# CM41x_M0 register map
Vendor: Analog Devices; Series: CM41x_M0; File version: 1p0
CPU: CM0 r0p0, little endian, MPU, FPU, 4 interrupt priority bits
Registers are 32-bit, read-write, reset 0x0 unless marked. A register's access mark holds for its fields unless they carry their own. Offsets are from the block's base; [hi:lo] are bit positions; {n}, {i} and the like mark numbered series; 'fields as' and 'values as' point back to an identical list.

## PWM0 — Pulse-Width Modulator
Base 0x40028000
Same registers: PWM1 0x40029000, PWM2 0x4002A000
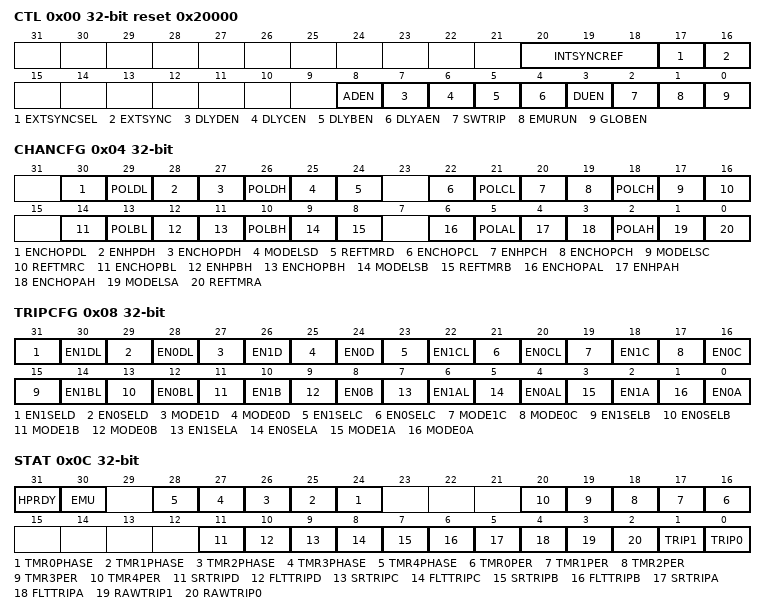
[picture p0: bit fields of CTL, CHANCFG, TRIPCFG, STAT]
0x00 CTL reset 0x20000 — Control Register
  [20:18] INTSYNCREF — Timer reference for Internal Sync
    {v}=INTSYNC_{v} (PWMTMR{v} provides sync reference) (v=0..4)
  [17] EXTSYNCSEL — External Sync Select
    0=EXTSYNC_ASYNC (Asynchronous External Sync); 1=EXTSYNC_SYNC (Synchronous External Sync)
  [16] EXTSYNC — External Sync
    0=INTSYNC (Internal sync used); 1=EXTSYNC (External sync used)
  [8] ADEN — Asymmetric Dead-time Enable
  [7] DLYDEN — Enable Delay Counter for Channel D
    0=DLYD_DIS (Disable); 1=DLYD_EN (Enable)
  [6] DLYCEN — Enable Delay Counter for Channel C
    0=DLYC_DIS (Disable); 1=DLYC_EN (Enable)
  [5] DLYBEN — Enable Delay Counter for Channel B
    0=DLYB_DIS (Disable); 1=DLYB_EN (Enable)
  [4] DLYAEN — Enable Delay Counter for Channel A
    0=DLYA_DIS (Disable); 1=DLYA_EN (Enable)
  [3] DUEN — Double Update Mode Enable
  [2] SWTRIP — Software Trip
  [1] EMURUN — Output Behavior During Emulation Mode
    0=EMURUN_DIS (Disable Outputs); 1=EMURUN_EN (Enable Outputs)
  [0] GLOBEN — Module Enable
    0=PWM_DIS (Disable); 1=PWM_EN (Enable)
0x04 CHANCFG — Channel Configuration Register
  [30] ENCHOPDL — Channel D Gate Chopping Enable Low Side
    0=CHOPDL_DIS (Disable Chopping Channel D Low Side); 1=CHOPDL_EN (Enable Chopping Channel D Low Side)
  [29] POLDL — Channel D low side Polarity
    0=DL_ACTLO (Active Low); 1=DL_ACTHI (Active High)
  [28] ENHPDH — Channel D heightened-precision enable for high side Output
    0=HPDH_DIS (Disable HP Output Channel D High); 1=HPDH_EN (Enable HP Output Channel D High)
  [27] ENCHOPDH — Channel D Gate Chopping Enable High Side
    0=CHOPDH_DIS (Disable Chopping Channel D High Side); 1=CHOPDH_EN (Enable Chopping Channel D High Side)
  [26] POLDH — Channel D High side Polarity
    0=DH_ACTLO (Active Low); 1=DH_ACTHI (Active High)
  [25] MODELSD — Channel D Mode of low Side Output
    0=LOD_INVHI (Invert of high output); 1=LOD_IND (Independent control)
  [24] REFTMRD — Channel D Timer Reference
    0=PWMTMR0 is Channel D reference; 1=PWMTMR4 is Channel D reference
  [22] ENCHOPCL — Channel C Gate Chopping Enable Low Side
    0=CHOPCL_DIS (Disable Chopping Channel C Low Side); 1=CHOPCL_EN (Enable Chopping Channel C Low Side)
  [21] POLCL — Channel C low side Polarity
    0=CL_ACTLO (Active Low); 1=CL_ACTHI (Active High)
  [20] ENHPCH — Channel C heightened-precision enable for high side Output
    0=HPCH_DIS (Disable HP Output Channel C High); 1=HPCH_EN (Enable HP Output Channel C High)
  [19] ENCHOPCH — Channel C Gate Chopping Enable High Side
    0=CHOPCH_DIS (Disable Chopping Channel C High Side); 1=CHOPCH_EN (Enable Chopping Channel C High Side)
  [18] POLCH — Channel C High side Polarity
    0=CH_ACTLO (Active Low); 1=CH_ACTHI (Active High)
  [17] MODELSC — Channel C Mode of low Side Output
    0=LOC_INVHI (Invert of high output); 1=LOC_IND (Independent control)
  [16] REFTMRC — Channel C Timer Reference
    0=PWMTMR0 is Channel C reference; 1=PWMTMR3 is Channel C reference
  [14] ENCHOPBL — Channel B Gate Chopping Enable Low Side
    0=CHOPBL_DIS (Disable Chopping Channel B Low Side); 1=CHOPBL_EN (Enable Chopping Channel B Low Side)
  [13] POLBL — Channel B low side Polarity
    0=BL_ACTLO (Active Low); 1=BL_ACTHI (Active High)
  [12] ENHPBH — Channel B heightened-precision enable for high side Output
    0=HPBH_DIS (Disable HP Output Channel B High); 1=HPBH_EN (Enable HP Output Channel B High)
  [11] ENCHOPBH — Channel B Gate Chopping Enable High Side
    0=CHOPBH_DIS (Disable Chopping Channel B High Side); 1=CHOPBH_EN (Enable Chopping Channel B High Side)
  [10] POLBH — Channel B High side Polarity
    0=BH_ACTLO (Active Low); 1=BH_ACTHI (Active High)
  [9] MODELSB — Channel B Mode of low Side Output
    0=LOB_INV (Invert of high output); 1=LOB_IND (Independent control)
  [8] REFTMRB — Channel B Timer Reference
    0=PWMTMR0 is Channel B reference; 1=PWMTMR2 is Channel B reference
  [6] ENCHOPAL — Channel A Gate Chopping Enable Low Side
    0=CHOPAL_DIS (Disable Chopping Channel A Low Side); 1=CHOPAL_EN (Enable Chopping Channel A Low Side)
  [5] POLAL — Channel A low side Polarity
    0=AL_ACTLO (Active Low); 1=AL_ACTHI (Active High)
  [4] ENHPAH — Channel A heightened-precision enable for high side Output
    0=HPAH_DIS (Disable HP Output Channel A High); 1=HPAH_EN (Enable HP Output Channel A High)
  [3] ENCHOPAH — Channel A Gate Chopping Enable High Side
    0=CHOPAH_DIS (Disable Chopping Channel A High Side); 1=CHOPAH_EN (Enable Chopping Channel A High Side)
  [2] POLAH — Channel A High side Polarity
    0=AH_ACTLO (Active Low); 1=AH_ACTHI (Active High)
  [1] MODELSA — Channel A Mode of low Side Output
    0=LOA_INVHI (Invert of high output); 1=LOA_IND (Independent control)
  [0] REFTMRA — Channel A Timer Reference
    0=PWMTMR0 is Channel A reference; 1=PWMTMR1 is Channel A reference
0x08 TRIPCFG — Trip Configuration Register
  [31] EN1SELD — TRIP1 Enable Select for Channel D Low Side
    0=TRIP1SEL_EN0D (Select EN0D for Channel D Low Side Trip1 Enable); 1=TRIP1SEL_EN0DL (Select EN0DL for Channel D Low Side Trip1 Enable)
  [30] EN1DL — Enable TRIP1 for Channel D Low Side
    0=TRIP1DL_DIS (Disable Trip1 for Channel D Low Side); 1=TRIP1DL_EN (Enable Trip1 for Channel D Low Side)
  [29] EN0SELD — TRIP0 Enable Select for Channel D Low Side
    0=TRIP0SEL_EN0D (Select EN0D for Channel D Low Side Trip0 Enable); 1=TRIP0SEL_EN0DL (Select EN0DL for Channel D Low Side Trip0 Enable)
  [28] EN0DL — Enable TRIP0 for Channel D Low Side
    0=TRIP0DL_DIS (Disable Trip0 for Channel D Low Side); 1=TRIP0DL_EN (Enable Trip0 for Channel D Low Side)
  [27] MODE1D — Mode of TRIP1 for Channel D
    0=TRIP1D_FLT (Fault Trip on TRIP1 Input); 1=TRIP1D_RSTRT (Self Restart on TRIP1 Input)
  [26] EN1D — Enable TRIP1 for Channel D
    0=TRIP1D_DIS (Disable TRIP1 for Channel D); 1=TRIP1D_EN (Enable TRIP1 for Channel D)
  [25] MODE0D — Mode of TRIP0 for Channel D
    0=TRIP0D_FLT (Fault Trip on TRIP0 Input); 1=TRIP0D_RSTRT (Self Restart on TRIP0 Input)
  [24] EN0D — Enable TRIP0 for Channel D
    0=TRIP0D_DIS (Disable TRIP0 for Channel D); 1=TRIP0D_EN (Enable TRIP0 for Channel D)
  [23] EN1SELC — TRIP1 Enable Select for Channel C Low Side
    0=TRIP1SEL_EN0C (Select EN0C for Channel C Low Side Trip1 Enable); 1=TRIP1SEL_EN0CL (Select EN0CL for Channel C Low Side Trip1 Enable)
  [22] EN1CL — Enable TRIP1 for Channel C Low Side
    0=TRIP1CL_DIS (Disable Trip1 for Channel C Low Side); 1=TRIP1CL_EN (Enable Trip1 for Channel C Low Side)
  [21] EN0SELC — TRIP0 Enable Select for Channel C Low Side
    0=TRIP0SEL_EN0C (Select EN0C for Channel C Low Side Trip0 Enable); 1=TRIP0SEL_EN0CL (Select EN0CL for Channel C Low Side Trip0 Enable)
  [20] EN0CL — Enable TRIP0 for Channel C Low Side
    0=TRIP0CL_DIS (Disable Trip0 for Channel C Low Side); 1=TRIP0CL_EN (Enable Trip0 for Channel C Low Side)
  [19] MODE1C — Mode of TRIP1 for Channel C
    0=TRIP1C_FLT (Fault Trip on TRIP1 Input); 1=TRIP1C_RSTRT (Self Restart on TRIP1 Input)
  [18] EN1C — Enable TRIP1 as a trip source for Channel C
    0=TRIP1C_DIS (Disable TRIP1 for Channel C); 1=TRIP1C_EN (Enable TRIP1 for Channel C)
  [17] MODE0C — Mode of TRIP0 for Channel C
    0=TRIP0C_FLT (Fault Trip on TRIP0 Input); 1=TRIP0C_RSTRT (Self Restart on TRIP0 Input)
  [16] EN0C — Enable TRIP0 for Channel C
    0=TRIP0C_DIS (Disable TRIP0 for Channel C); 1=TRIP0C_EN (Enable TRIP0 for Channel C)
  [15] EN1SELB — TRIP1 Enable Select for Channel B Low Side
    0=TRIP1SEL_EN0B (Select EN0B for Channel B Low Side Trip1 Enable); 1=TRIP1SEL_EN0BL (Select EN0BL for Channel B Low Side Trip1 Enable)
  [14] EN1BL — Enable TRIP1 as a trip source for Channel B Low Side
    0=TRIP1BL_DIS (Disable Trip1 for Channel B Low Side); 1=TRIP1BL_EN (Enable Trip1 for Channel B Low Side)
  [13] EN0SELB — TRIP0 Enable Select for Channel B Low Side
    0=TRIP0SEL_EN0B (Select EN0B for Channel B Low Side Trip0 Enable); 1=TRIP0SEL_EN0BL (Select EN0BL for Channel B Low Side Trip0 Enable)
  [12] EN0BL — Enable TRIP0 for Channel B Low Side
    0=TRIP0BL_DIS (Disable Trip0 for Channel B Low Side); 1=TRIP0BL_EN (Enable Trip0 for Channel B Low Side)
  [11] MODE1B — Mode of TRIP1 for Channel B
    0=TRIP1B_FLT (Fault Trip on TRIP1 Input); 1=TRIP1B_RSTRT (Self Restart on TRIP1 Input)
  [10] EN1B — Enable TRIP1 for Channel B
    0=TRIP1B_DIS (Disable TRIP1 for Channel B); 1=TRIP1B_EN (Enable TRIP1 for Channel B)
  [9] MODE0B — Mode of TRIP0 for Channel B
    0=TRIP0B_FLT (Fault Trip on TRIP0 Input); 1=TRIP0B_RSTRT (Self Restart on TRIP0 Input)
  [8] EN0B — Enable TRIP0 as a trip source for Channel B
    0=TRIP0B_DIS (Disable TRIP0 for Channel B); 1=TRIP0B_EN (Enable TRIP0 for Channel B)
  [7] EN1SELA — TRIP1 Enable Select for Channel A Low Side
    0=TRIP1SEL_EN0A (Select EN0A for Channel A Low Side Trip1 Enable); 1=TRIP1SEL_EN0AL (Select EN0AL for Channel A Low Side Trip1 Enable)
  [6] EN1AL — Enable TRIP1 for Channel A Low Side
    0=TRIP1AL_DIS (Disable Trip1 for Channel A Low Side); 1=TRIP1AL_EN (Enable Trip1 for Channel A Low Side)
  [5] EN0SELA — TRIP0 Enable Select for Channel A Low Side
    0=TRIP0SEL_EN0A (Select EN0A for Channel A Low Side Trip0 Enable); 1=TRIP0SEL_EN0AL (Select EN0AL for Channel A Low Side Trip0 Enable)
  [4] EN0AL — Enable TRIP0 for Channel A Low Side
    0=TRIP0AL_DIS (Disable Trip0 for Channel A Low Side); 1=TRIP0AL_EN (Enable Trip0 for Channel A Low Side)
  [3] MODE1A — Mode of TRIP1 for Channel A
    0=TRIP1A_FLT (Fault Trip on TRIP1 Input); 1=TRIP1A_RSTRT (Self Restart on TRIP1 Input)
  [2] EN1A — Enable TRIP1 as a trip source for Channel A
    0=TRIP1A_DIS (Disable TRIP1 for Channel A); 1=TRIP1A_EN (Enable TRIP1 for Channel A)
  [1] MODE0A — Mode of TRIP0 for Channel A
    0=TRIP0A_FLT (Fault Trip on TRIP0 Input); 1=TRIP0A_RSTRT (Self Restart on TRIP0 Input)
  [0] EN0A — Enable TRIP0 as a trip source for Channel A
    0=TRIP0A_DIS (Disable TRIP0 for Channel A); 1=TRIP0A_EN (Enable TRIP0 for Channel A)
0x0C STAT — Status Register
  [31] HPRDY ro — Heightened-Precision Ready Status
    0=NOT_HPRDY (HPPWM Not Ready For Operation); 1=HPRDY (HPPWM Ready For Operation)
  [30] EMU range 0x00000000..0x00000001 — Emulator Status
  [n+24] TMR{n}PHASE (n=0..4) — PWMTMR{n} Phase Status
    0=TMR{n}PH1 (1st Half Phase); 1=TMR{n}PH2 (2nd Half Phase)
  [n+16] TMR{n}PER (n=0..4) — PWMTMR{n} Period Boundary Status
    0=NOT_PER{n} (PWMTMR{n} period boundary not reached); 1=PER{n} (PWMTMR{n} period boundary reached)
  [11] SRTRIPD ro — Self-Restart Trip Status for Channel D
    0=SRD_NOTRIP (Channel D Self-Restart Trip Status is "not tripped"); 1=SRD_TRIP (Channel D Self-Restart Trip Status is "tripped")
  [10] FLTTRIPD — Fault Trip Status for Channel D
    0=FLTD_NOTRIP (Channel D Fault Trip Status is "not tripped"); 1=FLTD_TRIP (Channel D Fault Trip Status is "tripped")
  [9] SRTRIPC ro — Self-Restart Trip Status for Channel C
    0=SRC_NOTRIP (Channel C Self-Restart Trip Status is "not tripped"); 1=SRC_TRIP (Channel C Self-Restart Trip Status is "tripped")
  [8] FLTTRIPC — Fault Trip Status for Channel C
    0=FLTC_NOTRIP (Channel C Fault Trip Status is "not tripped"); 1=FLTC_TRIP (Channel C Fault Trip Status is "tripped")
  [7] SRTRIPB ro — Self-Restart Trip Status for Channel B
    0=SRB_NOTRIP (Channel B Self-Restart Trip Status is "not tripped"); 1=SRB_TRIP (Channel B Self-Restart Trip Status is "tripped")
  [6] FLTTRIPB — Fault Trip Status for Channel B
    0=FLTB_NOTRIP (Channel B Fault Trip Status is "not tripped"); 1=FLTB_TRIP (Channel A Fault Trip Status is "tripped")
  [5] SRTRIPA ro — Self-Restart Trip Status for Channel A
    0=SRA_NOTRIP (Channel A Self-Restart Trip Status is "not tripped"); 1=SRA_TRIP (Channel A Self-Restart Trip Status is "tripped")
  [4] FLTTRIPA — Fault Trip Status for Channel A
    0=FLTA_NOTRIP (Channel A Fault Trip Status is "not tripped"); 1=FLTA_TRIP (Channel A Fault Trip Status is "tripped")
  [3] RAWTRIP1 ro — Raw Trip 1 Status
    0=TRIP1LVL_LO (TRIP1 Level is Low); 1=TRIP1LVL_HI (TRIP1 Level is High)
  [2] RAWTRIP0 ro — Raw Trip 0 Status
    0=TRIP0LVL_LO (TRIP0 Level is Low); 1=TRIP0LVL_HI (TRIP0 Level is High)
  [1] TRIP1 — Status bit set when TRIP1 is active low
    0=NO_TRIP1 (TRIP1 status is "not tripped"); 1=TRIP1 (TRIP1 status is "tripped" (active low))
  [0] TRIP0 — Status bit set when TRIP0 is active low
    0=NO_TRIP0 (TRIP0 status is "not tripped"); 1=TRIP0 (TRIP0 status is "tripped" (active low))
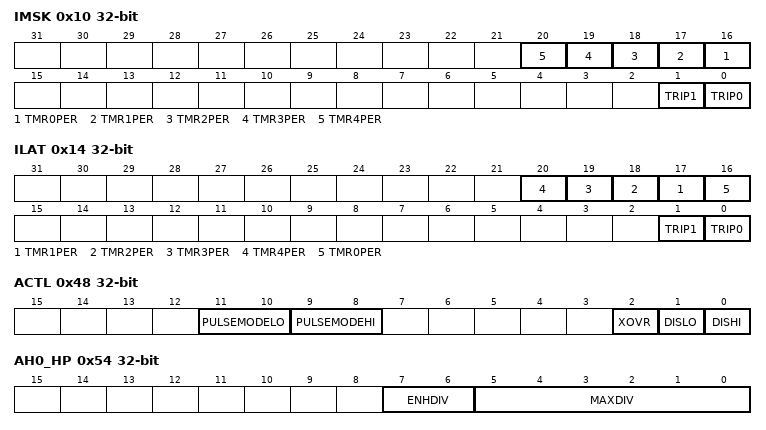
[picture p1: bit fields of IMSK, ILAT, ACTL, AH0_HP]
0x10 IMSK — Interrupt Mask Register
  [n+16] TMR{n}PER (n=0..4) — PWMTMR{n} Period Boundary Interrupt Enable
    0=PER{n}_MSK (Mask PWMTMR{n} Period Interrupt); 1=PER{n}_UMSK (Unmask PWMTMR{n} Period Interrupt)
  [1] TRIP1 — TRIP1 Interrupt Enable
    0=TRIP1_MSK (Mask TRIP1 Interrupt); 1=TRIP1_UMSK (Unmask TRIP1 Interrupt)
  [0] TRIP0 — TRIP0 Interrupt Enable
    0=TRIP0_MSK (Mask TRIP0 Interrupt); 1=TRIP0_UMSK (Unmask TRIP0 Interrupt)
0x14 ILAT — Interrupt Latch Register
  [n+16] TMR{n}PER (n=1..4) — PWMTMR{n} Period Latched Interrupt Status
    0=PER{n}_INTLO (No Interrupt Latched); 1=PER{n}_INTHI (Interrupt Latched)
  [16] TMR0PER — PWMTMR0 Period Boundary Interrupt Latched Status
    0=PER0_INTLO (No Interrupt Latched); 1=PER0_INTHI (Interrupt Latched)
  [1] TRIP1 — TRIP1 Interrupt Latched Status
    0=TRIP1_INTLO (No Interrupt Latched); 1=TRIP1_INTHI (Interrupt Latched)
  [0] TRIP0 — TRIP0 Interrupt Latched Status
    0=TRIP0_INTLO (No Interrupt Latched); 1=TRIP0_INTHI (Interrupt Latched)
0x18 CHOPCFG — Chop Configuration Register
  [7:0] VALUE range 0x00000000..0x000000FF — Gate Chopping Divisor
0x20 SYNC_WID reset 0x3FF — Sync Pulse Width Register
  [9:0] VALUE range 0x00000000..0x000003FF — Sync Pulse Width
{0x24+4i} TM{i} (i=0..4) — Timer {i} Period Register
  [15:0] VALUE range 0x00000000..0x0000FFFF — Timer PWMTMR{i} Period Value
0x38 DLYA — Channel A Delay Register
  [15:0] VALUE range 0x00000000..0x0000FFFF — Channel A Delay Value
0x3C DLYB — Channel B Delay Register
  [15:0] VALUE range 0x00000000..0x0000FFFF — Channel B Delay Value
0x40 DLYC — Channel C Delay Register
  [15:0] VALUE range 0x00000000..0x0000FFFF — Channel C Delay Value
0x44 DLYD — Channel D Delay Register
  [15:0] VALUE range 0x00000000..0x0000FFFF — Channel D Delay Value
0x48 ACTL — Channel A Control Register
  [11:10] PULSEMODELO — Low Side Output Pulse Position
    0=SYM_LO (Symmetrical); 1=ASYM_LO (Asymmetrical); 2=LEFT_LO (Left Half); 3=RIGHT_LO (Right Half)
  [9:8] PULSEMODEHI — High Side Output Pulse Position
    0=SYM_HI (Symmetrical); 1=ASYM_HI (Asymmetrical); 2=LEFT_HI (Left Half); 3=RIGHT_HI (Right Half)
  [2] XOVR — high-low Crossover Enable
    0=XOVR_DIS (Disable Crossover); 1=XOVR_EN (Enable Crossover)
  [1] DISLO — Channel Low Side Output Disable
    0=LO_DIS (Enable Low Side Output); 1=LO_EN (Disable Low Side Output)
  [0] DISHI — Channel High Side Output Disable
    0=HI_DIS (Enable High Side Output); 1=HI_EN (Disable High Side Output)
0x4C AH0 — Channel A-High Duty-0 Register
  [15:0] DUTY range 0x00000000..0x0000FFFF — Duty Cycle Asserted Count
0x50 AH1 — Channel A-High Duty-1 Register
  [15:0] DUTY range 0x00000000..0x0000FFFF — Duty Cycle De-Asserted Count
0x54 AH0_HP — Channel A-High Heightened-Precision Duty-0 Register
  [7:6] ENHDIV range 0x00000000..0x00000003 — Enhanced Precision Divider Bits
  [5:0] MAXDIV range 0x00000000..0x0000003F — Maximum Precision Supplementary Divider Bits
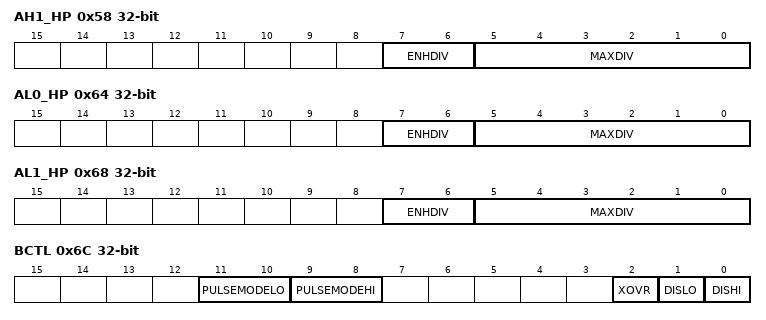
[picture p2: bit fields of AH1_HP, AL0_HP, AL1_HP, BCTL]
0x58 AH1_HP — Channel A-High Heightened-Precision Duty-1 Register
  fields as AH0_HP
0x5C AL0 — Channel A-Low Duty-0 Register
  [15:0] DUTY range 0x00000000..0x0000FFFF — Duty Cycle Asserted Count
0x60 AL1 — Channel A-Low Duty-1 Register
  fields as AH1
0x64 AL0_HP — Channel A-Low Heightened-Precision Duty-0 Register
  fields as AH0_HP
0x68 AL1_HP — Channel A-Low Heightened-Precision Duty-1 Register
  fields as AH0_HP
0x6C BCTL — Channel B Control Register
  [11:10] PULSEMODELO — Low Side Output Pulse Position
  [9:8] PULSEMODEHI — High Side Output Pulse Position
  [2] XOVR — high-low Crossover Enable
  [1] DISLO — Channel Low Side Output Disable
  [0] DISHI — Channel High Side Output Disable
0x70 BH0 — Channel B-High Duty-0 Register
  [15:0] DUTY range 0x00000000..0x0000FFFF — Duty Cycle Asserted Count
0x74 BH1 — Channel B-High Duty-1 Register
  fields as AH1
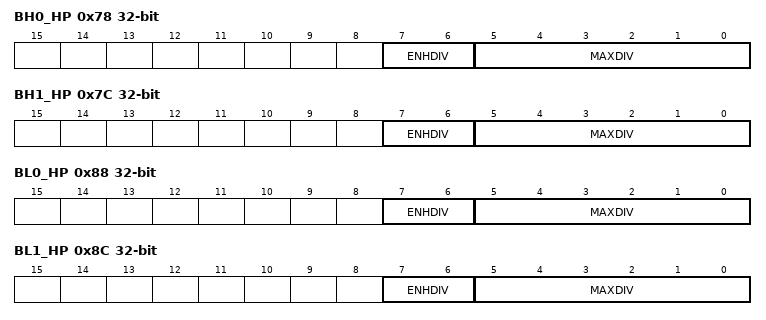
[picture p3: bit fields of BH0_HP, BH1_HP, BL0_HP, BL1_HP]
0x78 BH0_HP — Channel B-High Heightened-Precision Duty-0 Register
  fields as AH0_HP
0x7C BH1_HP — Channel B-High Heightened-Precision Duty-1 Register
  fields as AH0_HP
0x80 BL0 — Channel B-Low Duty-0 Register
  [15:0] DUTY range 0x00000000..0x0000FFFF — Duty Cycle Asserted Count
0x84 BL1 — Channel B-Low Duty-1 Register
  fields as AH1
0x88 BL0_HP — Channel B-Low Heightened-Precision Duty-0 Register
  fields as AH0_HP
0x8C BL1_HP — Channel B-Low Heightened-Precision Duty-1 Register
  fields as AH0_HP
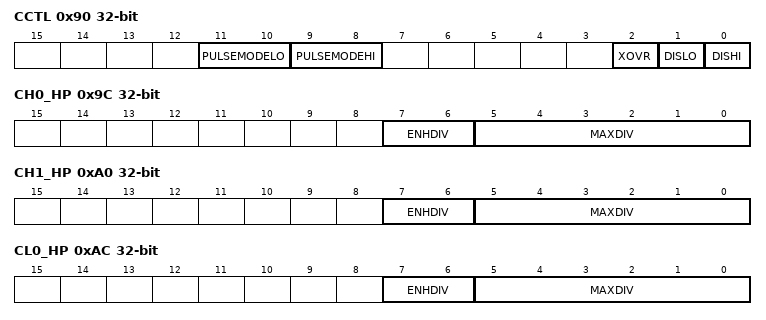
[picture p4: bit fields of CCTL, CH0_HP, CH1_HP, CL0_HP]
0x90 CCTL — Channel C Control Register
  fields as BCTL
0x94 CH0 — Channel C-High Pulse Duty Register 0
  [15:0] DUTY range 0x00000000..0x0000FFFF — Duty Cycle Asserted Count
0x98 CH1 — Channel C-High Pulse Duty Register 1
  fields as AH1
0x9C CH0_HP — Channel C-High Pulse Heightened-Precision Duty Register 0
  fields as AH0_HP
0xA0 CH1_HP — Channel C-High Pulse Heightened-Precision Duty Register 1
  fields as AH0_HP
0xA4 CL0 — Channel C-Low Pulse Duty Register 0
  [15:0] DUTY range 0x00000000..0x0000FFFF — Duty Cycle Asserted Count
0xA8 CL1 — Channel C-Low Duty-1 Register
  fields as AH1
0xAC CL0_HP — Channel C-Low Pulse Duty Register 1
  fields as AH0_HP
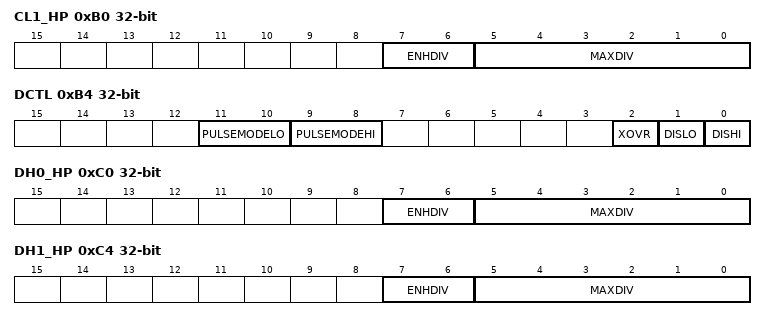
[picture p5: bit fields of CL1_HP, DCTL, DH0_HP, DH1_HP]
0xB0 CL1_HP — Channel C-Low Heightened-Precision Duty-1 Register
  fields as AH0_HP
0xB4 DCTL — Channel D Control Register
  fields as BCTL
0xB8 DH0 — Channel D-High Duty-0 Register
  [15:0] DUTY range 0x00000000..0x0000FFFF — Duty Cycle Asserted Count
0xBC DH1 — Channel D-High Pulse Duty Register 1
  fields as AH1
0xC0 DH0_HP — Channel D-High Pulse Heightened-Precision Duty Register 0
  fields as AH0_HP
0xC4 DH1_HP — Channel D High Pulse Heightened-Precision Duty Register 1
  fields as AH0_HP
0xC8 DL0 — Channel D-Low Pulse Duty Register 0
  [15:0] DUTY range 0x00000000..0x0000FFFF — Duty Cycle Asserted Count
0xCC DL1 — Channel D-Low Pulse Duty Register 1
  fields as AH1
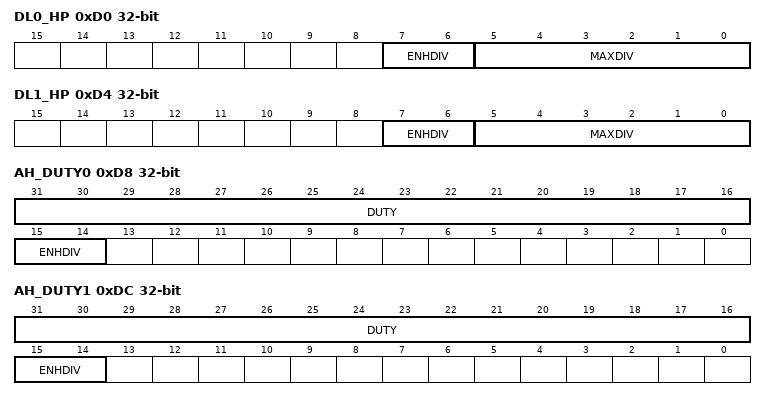
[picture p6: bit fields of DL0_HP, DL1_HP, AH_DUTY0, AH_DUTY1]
0xD0 DL0_HP — Channel D-Low Heightened-Precision Duty-0 Register
  fields as AH0_HP
0xD4 DL1_HP — Channel D-Low Heightened-Precision Duty-1 Register
  fields as AH0_HP
0xD8 AH_DUTY0 — Channel A-High Full Duty0 Register
  [31:16] DUTY range 0x00000000..0x0000FFFF — Coarse Duty Value
  [15:14] ENHDIV range 0x00000000..0x00000003 — Enhanced Precision Divider Bits
0xDC AH_DUTY1 — Channel A-High Full Duty1 Register
  fields as AH_DUTY0
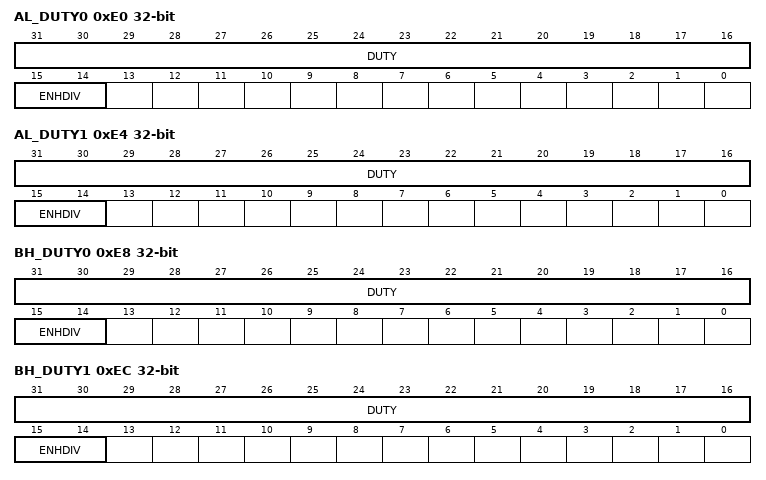
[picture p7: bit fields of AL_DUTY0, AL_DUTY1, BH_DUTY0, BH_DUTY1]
0xE0 AL_DUTY0 — Channel A-Low Full Duty0 Register
  fields as AH_DUTY0
0xE4 AL_DUTY1 — Channel A-Low Full Duty1 Register
  fields as AH_DUTY0
0xE8 BH_DUTY0 — Channel B-High Full Duty0 Register
  fields as AH_DUTY0
0xEC BH_DUTY1 — Channel B-High Full Duty1 Register
  fields as AH_DUTY0
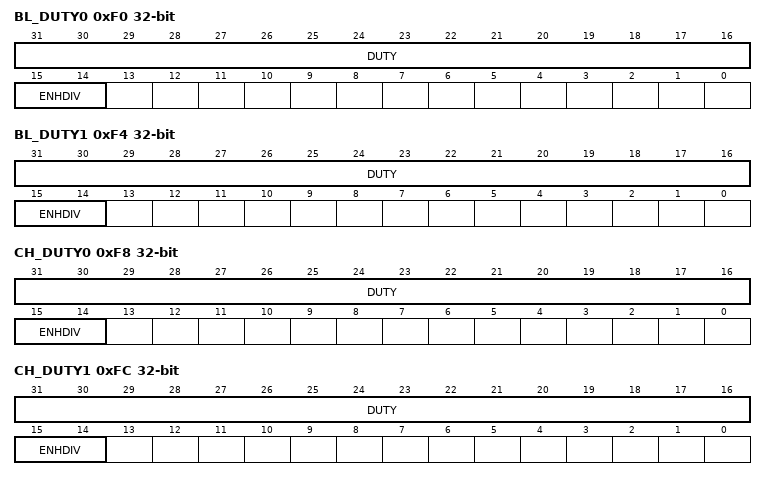
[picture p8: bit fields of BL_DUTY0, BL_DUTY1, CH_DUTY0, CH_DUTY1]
0xF0 BL_DUTY0 — Channel B-Low Full Duty0 Register
  fields as AH_DUTY0
0xF4 BL_DUTY1 — Channel B-Low Full Duty1 Register
  fields as AH_DUTY0
0xF8 CH_DUTY0 — Channel C-High Full Duty0 Register
  fields as AH_DUTY0
0xFC CH_DUTY1 — Channel C-High Full Duty1 Register
  fields as AH_DUTY0
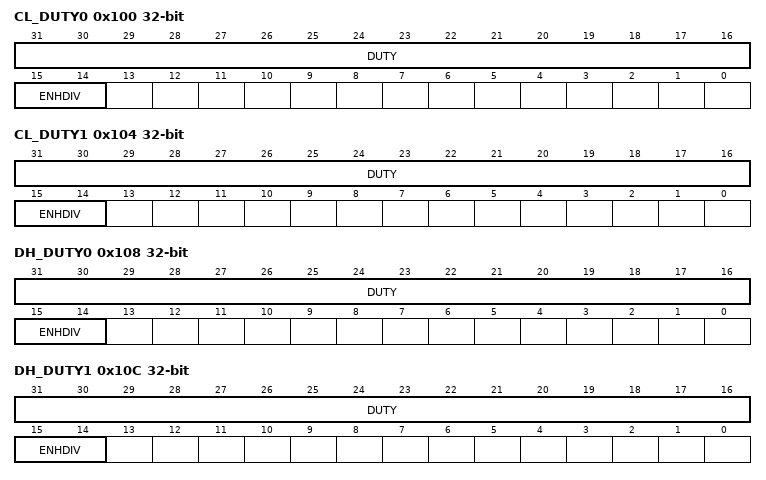
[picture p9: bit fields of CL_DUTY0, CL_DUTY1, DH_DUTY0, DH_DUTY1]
0x100 CL_DUTY0 — Channel C-Low Full Duty0 Register
  fields as AH_DUTY0
0x104 CL_DUTY1 — Channel C-Low Full Duty1 Register
  fields as AH_DUTY0
0x108 DH_DUTY0 — Channel D-High Full Duty0 Register
  fields as AH_DUTY0
0x10C DH_DUTY1 — Channel D-High Full Duty1 Register
  fields as AH_DUTY0
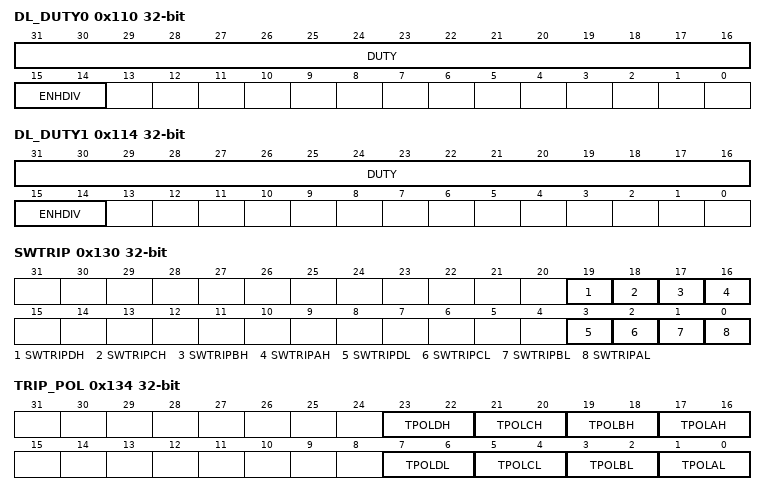
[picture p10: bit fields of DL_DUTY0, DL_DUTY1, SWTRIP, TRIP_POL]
0x110 DL_DUTY0 — Channel D-Low Full Duty0 Register
  fields as AH_DUTY0
0x114 DL_DUTY1 — Channel D-Low Full Duty1 Register
  fields as AH_DUTY0
0x118 CHA_DT — Channel A Dead-time Register
  [9:0] VALUE range 0x00000000..0x000003FF — Dead-time value
0x11C CHB_DT — Channel B Dead-time Register
  [9:0] VALUE range 0x00000000..0x000003FF — Dead-time value
0x120 CHC_DT — Channel C Dead-time Register
  [9:0] VALUE range 0x00000000..0x000003FF — Dead-time value
0x124 CHD_DT — Channel D Dead-time Register
  [9:0] VALUE range 0x00000000..0x000003FF — Dead-time value
0x130 SWTRIP — Software Trip Register
  [19] SWTRIPDH range 0x00000000..0x00000001 — Software Trip Bit for Channel D High Side
  [18] SWTRIPCH range 0x00000000..0x00000001 — Software Trip Bit for Channel C High Side
  [17] SWTRIPBH range 0x00000000..0x00000001 — Software Trip Bit for Channel B High Side
  [16] SWTRIPAH range 0x00000000..0x00000001 — Software Trip Bit for Channel A High Side
  [3] SWTRIPDL range 0x00000000..0x00000001 — Software Trip Bit for Channel D Low Side
  [2] SWTRIPCL range 0x00000000..0x00000001 — Software Trip Bit for Channel C Low Side
  [1] SWTRIPBL range 0x00000000..0x00000001 — Software Trip Bit for Channel B Low Side
  [0] SWTRIPAL range 0x00000000..0x00000001 — Software Trip Bit for Channel A Low Side
0x134 TRIP_POL — Trip Polarity Register
  [23:22] TPOLDH — Channel D High Side Trip Polarity
    0=TPOLDH_DIS (Set Channel D High Side to Inactive Polarity upon Trip); 1=TPOLDH_EN (Set Channel D High Side to Active Polarity upon Trip); 2=TPOLDH_HIZ (Set Channel D High Side to High Impedance upon Trip)
  [21:20] TPOLCH — Channel C High Side Trip Polarity
    0=TPOLCH_DIS (Set Channel C High Side to Inactive Polarity upon Trip); 1=TPOLCH_EN (Set Channel C High Side to Active Polarity upon Trip); 2=TPOLCH_HIZ (Set Channel C High Side to High Impedance upon Trip)
  [19:18] TPOLBH — Channel B High Side Trip Polarity
    0=TPOLBH_DIS (Set Channel B High Side to Inactive Polarity upon Trip); 1=TPOLBH_EN (Set Channel B High Side to Active Polarity upon Trip); 2=TPOLBH_HIZ (Set Channel B High Side to High Impedance upon Trip)
  [17:16] TPOLAH — Channel A High Side Trip Polarity
    0=TPOLAH_DIS (Set Channel A High Side to Inactive Polarity upon Trip); 1=TPOLAH_EN (Set Channel A High Side to Active Polarity upon Trip); 2=TPOLAH_HIZ (Set Channel A High Side to High Impedance upon Trip)
  [7:6] TPOLDL — Channel D Low Side Trip Polarity
    0=TPOLDL_DIS (Set Channel D Low Side to Inactive Polarity upon Trip); 1=TPOLDL_EN (Set Channel D Low Side to Active Polarity upon Trip); 2=TPOLDL_HIZ (Set Channel D Low Side to High Impedance upon Trip)
  [5:4] TPOLCL — Channel C Low Side Trip Polarity
    0=TPOLCL_DIS (Set Channel C Low Side to Inactive Polarity upon Trip); 1=TPOLCL_EN (Set Channel C Low Side to Active Polarity upon Trip); 2=TPOLCL_HIZ (Set Channel C Low Side to High Impedance upon Trip)
  [3:2] TPOLBL — Channel B Low Side Trip Polarity
    0=TPOLBL_DIS (Set Channel B Low Side to Inactive Polarity upon Trip); 1=TPOLBL_EN (Set Channel B Low Side to Active Polarity upon Trip); 2=TPOLBL_HIZ (Set Channel B Low Side to High Impedance upon Trip)
  [1:0] TPOLAL — Channel A Low Side Trip Polarity
    0=TPOLAL_DIS (Set Channel A Low Side to Inactive Polarity upon Trip); 1=TPOLAL_EN (Set Channel A Low Side to Active Polarity upon Trip); 2=TPOLAL_HIZ (Set Channel A Low Side to High Impedance upon Trip)
